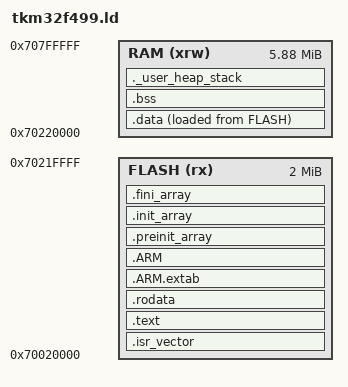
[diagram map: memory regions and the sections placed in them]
/**
 * TKM32F499 Linker Script
 *
 * Memory layout for TKM32F499 microcontroller
 * - SDRAM: 8MB (internal stacked die)
 * - QSPI Flash: 16MB (external, memory-mapped)
 *
 * Code executes from memory-mapped QSPI flash region.
 */

/* Entry Point */
ENTRY(Reset_Handler)

/* Highest address of the user mode stack */
_estack = 0x70220000;    /* End of 2MB SDRAM region */

/* Memory Definitions */
/* Bootloader loads code to SDRAM at 0x70020000 */
/* Internal SRAM at 0x20000000 is used for vector table (copied at runtime) */
MEMORY
{
    FLASH (rx)  : ORIGIN = 0x70020000, LENGTH = 0x200000   /* 2MB SDRAM - code runs here */
    RAM (xrw)   : ORIGIN = 0x70220000, LENGTH = 0x5E0000   /* Remaining SDRAM for data */
}

/* Sections */
SECTIONS
{
    /* Startup code goes first into FLASH */
    .isr_vector :
    {
        . = ALIGN(4);
        KEEP(*(.isr_vector))
        . = ALIGN(4);
    } >FLASH

    /* Program code and other data goes into FLASH */
    .text :
    {
        . = ALIGN(4);
        *(.text)
        *(.text*)
        *(.glue_7)
        *(.glue_7t)
        *(.eh_frame)

        KEEP (*(.init))
        KEEP (*(.fini))

        . = ALIGN(4);
        _etext = .;
    } >FLASH

    /* Constant data goes into FLASH */
    .rodata :
    {
        . = ALIGN(4);
        *(.rodata)
        *(.rodata*)
        . = ALIGN(4);
    } >FLASH

    .ARM.extab :
    {
        *(.ARM.extab* .gnu.linkonce.armextab.*)
    } >FLASH

    .ARM :
    {
        __exidx_start = .;
        *(.ARM.exidx*)
        __exidx_end = .;
    } >FLASH

    .preinit_array :
    {
        PROVIDE_HIDDEN (__preinit_array_start = .);
        KEEP (*(.preinit_array*))
        PROVIDE_HIDDEN (__preinit_array_end = .);
    } >FLASH

    .init_array :
    {
        PROVIDE_HIDDEN (__init_array_start = .);
        KEEP (*(SORT(.init_array.*)))
        KEEP (*(.init_array*))
        PROVIDE_HIDDEN (__init_array_end = .);
    } >FLASH

    .fini_array :
    {
        PROVIDE_HIDDEN (__fini_array_start = .);
        KEEP (*(SORT(.fini_array.*)))
        KEEP (*(.fini_array*))
        PROVIDE_HIDDEN (__fini_array_end = .);
    } >FLASH

    /* Used by the startup to initialize data */
    _sidata = LOADADDR(.data);

    /* Initialized data sections goes into RAM, load LMA copy after code */
    .data :
    {
        . = ALIGN(4);
        _sdata = .;
        *(.data)
        *(.data*)

        . = ALIGN(4);
        _edata = .;
    } >RAM AT> FLASH

    /* Uninitialized data section */
    . = ALIGN(4);
    .bss :
    {
        _sbss = .;
        __bss_start__ = _sbss;
        *(.bss)
        *(.bss*)
        *(COMMON)

        . = ALIGN(4);
        _ebss = .;
        __bss_end__ = _ebss;
    } >RAM

    /* User_heap_stack section */
    ._user_heap_stack :
    {
        . = ALIGN(8);
        PROVIDE ( end = . );
        PROVIDE ( _end = . );
        . = . + 0x2000;  /* Heap size: 8KB */
        . = . + 0x2000;  /* Stack size: 8KB */
        . = ALIGN(8);
    } >RAM

    /* Remove information from the standard libraries */
    /DISCARD/ :
    {
        libc.a ( * )
        libm.a ( * )
        libgcc.a ( * )
    }

    .ARM.attributes 0 : { *(.ARM.attributes) }
}
